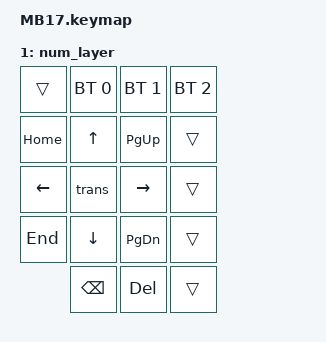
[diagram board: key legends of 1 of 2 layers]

/*
 * Copyright (c) 2022 The ZMK Contributors
 *
 * SPDX-License-Identifier: MIT
 */

#include <behaviors.dtsi>
#include <dt-bindings/zmk/keys.h>
#include <dt-bindings/zmk/bt.h>

/ {
    keymap {
        compatible = "zmk,keymap";

        default_layer {

            bindings = <
    &kp LOCKING_NU  &kp KP_SLASH    &kp KP_MULTIPLY &kp KP_MINUS
    &kp KP_NUMBER_7 &kp KP_NUMBER_8 &kp KP_NUMBER_9 
    &kp KP_NUMBER_4 &kp KP_NUMBER_5 &kp KP_NUMBER_6 &kp KP_PLUS
    &kp KP_NUMBER_1 &kp KP_NUMBER_2 &kp KP_NUMBER_3 
                    &kp KP_NUMBER_0 &kp KP_DOT      &kp KP_ENTER
            >;

            sensor-bindings = <&inc_dec_kp C_VOL_UP C_VOL_DN &inc_dec_kp PG_UP PG_DN>;
        };

        num_layer {
            bindings = <
    &trans          &bt BT_SEL 0   &bt BT_SEL 1     &bt BT_SEL 2
    &kp HOME        &kp UP_ARROW   &kp PAGE_UP      &trans
    &kp LEFT_ARROW  &   trans      &kp RIGHT_ARROW  &trans
    &kp END         &kp DOWN_ARROW &kp PAGE_DOWN    &trans
                    &kp BACKSPACE  &kp DELETE       &trans
            >;

        };
    };
};
